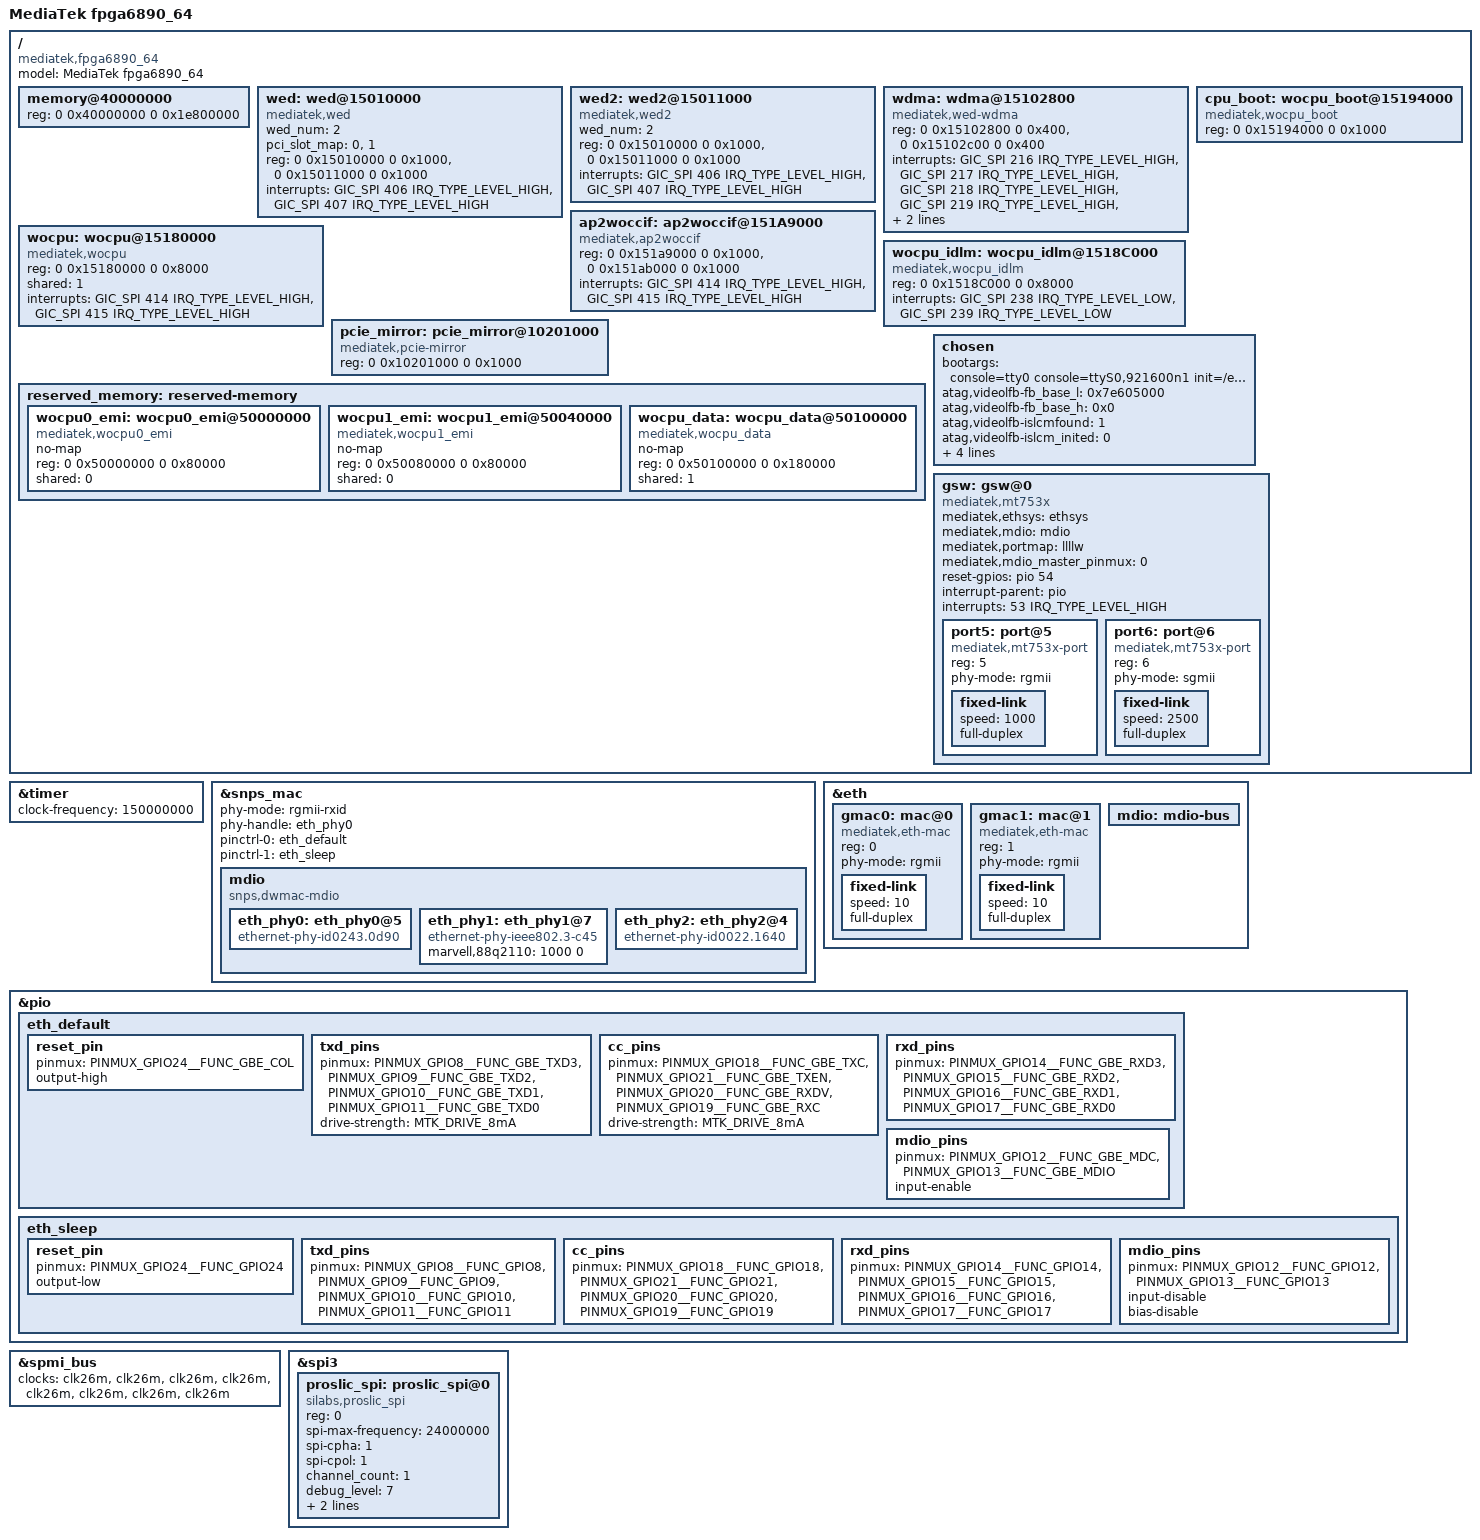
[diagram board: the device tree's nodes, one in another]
// SPDX-License-Identifier: GPL-2.0
/*
 * Copyright (c) 2019 MediaTek Inc.
 */

/dts-v1/;
#include <dt-bindings/interrupt-controller/irq.h>
#include <dt-bindings/interrupt-controller/arm-gic.h>
#include "mt6890.dtsi"

&reserved_memory {
};

/ {
	model = "MediaTek fpga6890_64";
	compatible = "mediatek,fpga6890_64", "mediatek,mt6890";

	memory@40000000 {
		device_type = "memory";
		reg = <0 0x40000000 0 0x1e800000>;
	};

	wed: wed@15010000 {
		compatible = "mediatek,wed";
		wed_num = <2>;
		/* add this property for wed get the pci slot number. */
		pci_slot_map = <0>, <1>;
		reg = <0 0x15010000 0 0x1000>,
				<0 0x15011000 0 0x1000>;
		interrupts = <GIC_SPI 406 IRQ_TYPE_LEVEL_HIGH>,
						<GIC_SPI 407 IRQ_TYPE_LEVEL_HIGH>;
	};

	wed2: wed2@15011000 {
		compatible = "mediatek,wed2";
		wed_num = <2>;
		reg = <0 0x15010000 0 0x1000>,
				<0 0x15011000 0 0x1000>;
		interrupts = <GIC_SPI 406 IRQ_TYPE_LEVEL_HIGH>,
						<GIC_SPI 407 IRQ_TYPE_LEVEL_HIGH>;
	};

	wdma: wdma@15102800 {
		compatible = "mediatek,wed-wdma";
		reg = <0 0x15102800 0 0x400>,
				<0 0x15102c00 0 0x400>;
		interrupts = <GIC_SPI 216 IRQ_TYPE_LEVEL_HIGH>,
						<GIC_SPI 217 IRQ_TYPE_LEVEL_HIGH>,
						<GIC_SPI 218 IRQ_TYPE_LEVEL_HIGH>,
						<GIC_SPI 219 IRQ_TYPE_LEVEL_HIGH>,
						<GIC_SPI 220 IRQ_TYPE_LEVEL_HIGH>,
						<GIC_SPI 221 IRQ_TYPE_LEVEL_HIGH>;
	};

	ap2woccif: ap2woccif@151A9000 {
		compatible = "mediatek,ap2woccif";
		reg = <0 0x151a9000 0 0x1000>,
				<0 0x151ab000 0 0x1000>;
		interrupts = <GIC_SPI 414 IRQ_TYPE_LEVEL_HIGH>,
						<GIC_SPI 415 IRQ_TYPE_LEVEL_HIGH>;
	};

	wocpu: wocpu@15180000 {
		compatible = "mediatek,wocpu";
		reg = <0 0x15180000 0 0x8000>;
		shared = <1>;
		interrupts = <GIC_SPI 414 IRQ_TYPE_LEVEL_HIGH>,
						<GIC_SPI 415 IRQ_TYPE_LEVEL_HIGH>;
	};

	wocpu_idlm: wocpu_idlm@1518C000 {
		compatible = "mediatek,wocpu_idlm";
		reg = <0 0x1518C000 0 0x8000>;
		interrupts = <GIC_SPI 238 IRQ_TYPE_LEVEL_LOW>,
						<GIC_SPI 239 IRQ_TYPE_LEVEL_LOW>;
	};

	cpu_boot: wocpu_boot@15194000 {
		compatible = "mediatek,wocpu_boot";
		reg = <0 0x15194000 0 0x1000>;
	};

	pcie_mirror: pcie_mirror@10201000 {
		compatible = "mediatek,pcie-mirror";
		reg = <0 0x10201000 0 0x1000>;
   	};

	reserved_memory: reserved-memory {
		#address-cells = <2>;
		#size-cells = <2>;
		ranges;

		wocpu0_emi: wocpu0_emi@50000000 {
			compatible = "mediatek,wocpu0_emi";
			no-map;
			reg = <0 0x50000000 0 0x80000>;
			shared = <0>;
		};

		wocpu1_emi: wocpu1_emi@50040000 {
			compatible = "mediatek,wocpu1_emi";
			no-map;
			reg = <0 0x50080000 0 0x80000>;
			shared = <0>;
		};

		wocpu_data: wocpu_data@50100000 {
			compatible = "mediatek,wocpu_data";
			no-map;
			reg = <0 0x50100000 0 0x180000>;
			shared = <1>;
		};
	};

	chosen {
		bootargs = "console=tty0 console=ttyS0,921600n1 \
		init=/etc/preinit root=/dev/mmcblk0p31 \
		loglevel=8 \
		androidboot.selinux=permissive androidboot.hardware=mt6880 \
		earlycon=mtk8250,mmio32,0x11002000 \
		mtk_printk_ctrl.disable_uart=0 \
		initcall_debug=1";

		atag,videolfb-fb_base_l = <0x7e605000>;
		atag,videolfb-fb_base_h = <0x0>;
		atag,videolfb-islcmfound = <1>;
		atag,videolfb-islcm_inited = <0>;
		atag,videolfb-fps= <6000>;
		atag,videolfb-vramSize= <0x1be0000>;
		atag,videolfb-lcmname=
			"nt35595_fhd_dsi_cmd_truly_nt50358_drv";
	};

	gsw: gsw@0 {
		compatible = "mediatek,mt753x";
		mediatek,ethsys = <&ethsys>;
		#address-cells = <1>;
		#size-cells = <0>;
	};
};

&timer {
	clock-frequency = <150000000>;
};


&snps_mac {
	phy-mode ="rgmii-rxid";
	phy-handle = <&eth_phy0>;
	status = "okay";
	pinctrl-names = "default", "sleep";
	pinctrl-0 = <&eth_default>;
	pinctrl-1 = <&eth_sleep>;
	mdio {
		compatible = "snps,dwmac-mdio";
		#address-cells = <1>;
		#size-cells = <0>;
		eth_phy0: eth_phy0@5 {
			compatible = "ethernet-phy-id0243.0d90";
		};
		eth_phy1: eth_phy1@7 {
			compatible = "ethernet-phy-ieee802.3-c45";
			marvell,88q2110 = <1000 0>;
		};
		eth_phy2: eth_phy2@4 {
			compatible = "ethernet-phy-id0022.1640";
		};
	};
};

&eth {
	status = "okay";
	gmac0: mac@0 {
		compatible = "mediatek,eth-mac";
		reg = <0>;
		phy-mode = "rgmii";
		fixed-link {
			speed = <10>;
			full-duplex;
		};
	};
	gmac1: mac@1 {
		compatible = "mediatek,eth-mac";
		reg = <1>;
		phy-mode = "rgmii";
		fixed-link {
			speed = <10>;
			full-duplex;
		};
	};
	mdio: mdio-bus {
		#address-cells = <1>;
		#size-cells = <0>;
	};
};

&gsw {
	mediatek,mdio = <&mdio>;
	mediatek,portmap = "llllw";
	mediatek,mdio_master_pinmux = <0>;
	reset-gpios = <&pio 54 0>;
	interrupt-parent = <&pio>;
	interrupts = <53 IRQ_TYPE_LEVEL_HIGH>;
	status = "okay";

	port5: port@5 {
		compatible = "mediatek,mt753x-port";
		reg = <5>;
		phy-mode = "rgmii";
		fixed-link {
			speed = <1000>;
			full-duplex;
		};
	};

	port6: port@6 {
		compatible = "mediatek,mt753x-port";
		reg = <6>;
		phy-mode = "sgmii";
		fixed-link {
			speed = <2500>;
			full-duplex;
		};
	};
};
/*
&odm {
	vibrator0:vibrator@0 {
		compatible = "mediatek,vibrator";
		vib_timer = <25>;
		vib_limit = <9>;
		vib_vol= <9>;
	};
};*/

&pio {
	eth_default: eth_default {
		reset_pin {
			pinmux = <PINMUX_GPIO24__FUNC_GBE_COL>;
			output-high;
		};
		txd_pins {
			pinmux = <PINMUX_GPIO8__FUNC_GBE_TXD3>,
				 <PINMUX_GPIO9__FUNC_GBE_TXD2>,
				 <PINMUX_GPIO10__FUNC_GBE_TXD1>,
				 <PINMUX_GPIO11__FUNC_GBE_TXD0>;
			drive-strength = <MTK_DRIVE_8mA>;
		};
		cc_pins {
			pinmux = <PINMUX_GPIO18__FUNC_GBE_TXC>,
				 <PINMUX_GPIO21__FUNC_GBE_TXEN>,
				 <PINMUX_GPIO20__FUNC_GBE_RXDV>,
				 <PINMUX_GPIO19__FUNC_GBE_RXC>;
			drive-strength = <MTK_DRIVE_8mA>;
		};
		rxd_pins {
			pinmux = <PINMUX_GPIO14__FUNC_GBE_RXD3>,
				 <PINMUX_GPIO15__FUNC_GBE_RXD2>,
				 <PINMUX_GPIO16__FUNC_GBE_RXD1>,
				 <PINMUX_GPIO17__FUNC_GBE_RXD0>;
		};
		mdio_pins {
			pinmux = <PINMUX_GPIO12__FUNC_GBE_MDC>,
				 <PINMUX_GPIO13__FUNC_GBE_MDIO>;
			input-enable;
		};
	};

	eth_sleep: eth_sleep {
		reset_pin {
			pinmux = <PINMUX_GPIO24__FUNC_GPIO24>;
			output-low;
		};
		txd_pins {
			pinmux = <PINMUX_GPIO8__FUNC_GPIO8>,
				 <PINMUX_GPIO9__FUNC_GPIO9>,
				 <PINMUX_GPIO10__FUNC_GPIO10>,
				 <PINMUX_GPIO11__FUNC_GPIO11>;
		};
		cc_pins {
			pinmux = <PINMUX_GPIO18__FUNC_GPIO18>,
				 <PINMUX_GPIO21__FUNC_GPIO21>,
				 <PINMUX_GPIO20__FUNC_GPIO20>,
				 <PINMUX_GPIO19__FUNC_GPIO19>;
		};
		rxd_pins {
			pinmux = <PINMUX_GPIO14__FUNC_GPIO14>,
				 <PINMUX_GPIO15__FUNC_GPIO15>,
				 <PINMUX_GPIO16__FUNC_GPIO16>,
				 <PINMUX_GPIO17__FUNC_GPIO17>;
		};
		mdio_pins {
			pinmux = <PINMUX_GPIO12__FUNC_GPIO12>,
				 <PINMUX_GPIO13__FUNC_GPIO13>;
			input-disable;
			bias-disable;
		};
	};
};

/* DISPSYS GPIO standardization */
#if 0
&pio {
	mtkfb_pins_lcd_bias_enp1: lcd_bias_enp1_gpio {
		pins_cmd_dat {
			pinmux = <PINMUX_GPIO28__FUNC_GPIO28>;
			slew-rate = <1>;
			output-high;
		};
	};

	mtkfb_pins_lcd_bias_enp0: lcd_bias_enp0_gpio {
		pins_cmd_dat {
			pinmux = <PINMUX_GPIO28__FUNC_GPIO28>;
			slew-rate = <1>;
			output-low;
		};
	};

	mtkfb_pins_lcd_bias_enn1: lcd_bias_enn1_gpio {
		pins_cmd_dat {
			pinmux = <PINMUX_GPIO29__FUNC_GPIO29>;
			slew-rate = <1>;
			output-high;
		};
	};

	mtkfb_pins_lcd_bias_enn0: lcd_bias_enn0_gpio {
		pins_cmd_dat {
			pinmux = <PINMUX_GPIO29__FUNC_GPIO29>;
			slew-rate = <1>;
			output-low;
		};
	};

	mtkfb_pins_lcm_rst_out1_gpio: lcm_rst_out1_gpio {
		pins_cmd_dat {
			pinmux = <PINMUX_GPIO42__FUNC_GPIO42>;
			slew-rate = <1>;
			output-high;
		};
	};

	mtkfb_pins_lcm_rst_out0_gpio: lcm_rst_out0_gpio {
		pins_cmd_dat {
			pinmux = <PINMUX_GPIO42__FUNC_GPIO42>;
			slew-rate = <1>;
			output-low;
		};
	};
	mtkfb_pins_lcm_dsi_te: lcm_dsi_te {
		pins_cmd_dat {
			pinmux = <PINMUX_GPIO41__FUNC_DSI_TE>;
		};
	};
};

&mtkfb {
	pinctrl-names = "lcd_bias_enp1_gpio", "lcd_bias_enp0_gpio",
		"lcd_bias_enn1_gpio", "lcd_bias_enn0_gpio",
		"lcm_rst_out1_gpio", "lcm_rst_out0_gpio",
		"mode_te_te";
	pinctrl-0 = <&mtkfb_pins_lcd_bias_enp1>;
	pinctrl-1 = <&mtkfb_pins_lcd_bias_enp0>;
	pinctrl-2 = <&mtkfb_pins_lcd_bias_enn1>;
	pinctrl-3 = <&mtkfb_pins_lcd_bias_enn0>;
	pinctrl-4 = <&mtkfb_pins_lcm_rst_out1_gpio>;
	pinctrl-5 = <&mtkfb_pins_lcm_rst_out0_gpio>;
	pinctrl-6 = <&mtkfb_pins_lcm_dsi_te>;
	status = "okay";
};
#endif

&spmi_bus {
	clocks = <&clk26m>,
		<&clk26m>,
		<&clk26m>,
		<&clk26m>,
		<&clk26m>,
		<&clk26m>,
		<&clk26m>,
		<&clk26m>;
	clock-names = "pmif_sys_ck",
		"pmif_tmr_ck",
		"pmif_clk_mux",
		"pmif_clk_osc_d10",
		"pmif_clk26m",
		"spmimst_clk_mux",
		"spmimst_clk26m",
		"spmimst_clk_osc_d10";
};
&spi3 {
	status = "okay";
	#address-cells=<1>;
	#size-cells=<0>;

	proslic_spi: proslic_spi@0 {
		compatible = "silabs,proslic_spi";
		reg = <0>;
		spi-max-frequency = <24000000>;
		spi-cpha = <1>;
		spi-cpol = <1>;
		channel_count = <1>;
		debug_level = <7>;       /* 1 = TRC, 2 = DBG, 4 = ERR */
		reset_gpio = <&pio 23 0>;       /* Hz */
		ig,enable-spi = <1>;                /* 1: Enable, 0: Disable */
	};
};
/* GPS GPIO standardization start */
#if 0
&pio {
	gps_pins_default: gps_default {
	};

	gps_l1_lna_pins_ol: gps_l1_lna@0 {
		pins_cmd_dat {
			pinmux = <PINMUX_GPIO125__FUNC_GPIO125>;
			output-low;
		};
	};
	gps_l1_lna_pins_dsp_ctrl: gps_l1_lna@1 {
		pins_cmd_dat {
			pinmux = <PINMUX_GPIO125__FUNC_GPS_L1_ELNA_EN>;
		};
	};
	gps_l1_lna_pins_oh: gps_l1_lna@2 {
		pins_cmd_dat {
			pinmux = <PINMUX_GPIO125__FUNC_GPIO125>;
			output-high;
		};
	};

	gps_l5_lna_pins_ol: gps_l5_lna@0 {
		pins_cmd_dat {
			pinmux = <PINMUX_GPIO126__FUNC_GPIO126>;
			output-low;
		};
	};
	gps_l5_lna_pins_dsp_ctrl: gps_l5_lna@1 {
		pins_cmd_dat {
			pinmux = <PINMUX_GPIO126__FUNC_GPS_L5_ELNA_EN>;
		};
	};
	gps_l5_lna_pins_oh: gps_l5_lna@2 {
		pins_cmd_dat {
			pinmux = <PINMUX_GPIO126__FUNC_GPIO126>;
			output-high;
		};
	};
};

&gps {
	pinctrl-names = "default",
		"gps_l1_lna_disable",
		"gps_l1_lna_dsp_ctrl",
		"gps_l1_lna_enable",
		"gps_l5_lna_disable",
		"gps_l5_lna_dsp_ctrl",
		"gps_l5_lna_enable";
	pinctrl-0 = <&gps_pins_default>;
	pinctrl-1 = <&gps_l1_lna_pins_ol>;
	pinctrl-2 = <&gps_l1_lna_pins_dsp_ctrl>;
	pinctrl-3 = <&gps_l1_lna_pins_oh>;
	pinctrl-4 = <&gps_l5_lna_pins_ol>;
	pinctrl-5 = <&gps_l5_lna_pins_dsp_ctrl>;
	pinctrl-6 = <&gps_l5_lna_pins_oh>;
	status = "okay";
};
#endif
/* GPS GPIO standardization end */

/*End of this file, DO NOT ADD ANYTHING HERE*/
